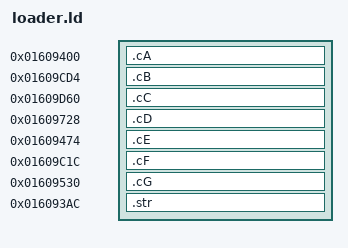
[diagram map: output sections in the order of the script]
SECTIONS {
  .cA 0x01609400 : { *(.cA) }
  .cB 0x01609cd4 : { *(.cB) }
  .cC 0x01609d60 : { *(.cC) }
  .cD 0x01609728 : { *(.cD) }
  .cE 0x01609474 : { *(.cE) }
  .cF 0x01609c1c : { *(.cF) }
  .cG 0x01609530 : { *(.cG) }
  .str 0x016093ac : { *(.str) }
  /DISCARD/ : { *(*) }
}
